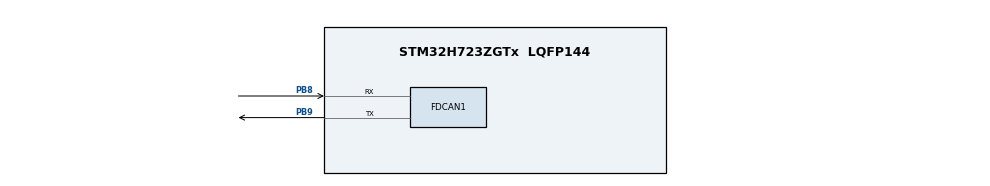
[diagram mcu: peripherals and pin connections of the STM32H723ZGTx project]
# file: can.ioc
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CORTEX_M7.default_mode_Activation=1
FDCAN1.CalculateBaudRateNominal=1000000
FDCAN1.CalculateTimeBitNominal=1000
FDCAN1.CalculateTimeQuantumNominal=41.666666666666664
FDCAN1.NominalPrescaler=2
FDCAN1.NominalTimeSeg1=20
FDCAN1.NominalTimeSeg2=3
FDCAN1.RxFifo0ElmtsNbr=8
FDCAN1.TxEventsNbr=4
FDCAN1.TxFifoQueueElmtsNbr=4
Mcu.Family=STM32H7
Mcu.Name=STM32H723ZGTx
Mcu.Package=LQFP144
NVIC.PriorityGroup=NVIC_PRIORITYGROUP_4
PB8.Mode=FDCAN_Activate
PB8.Signal=FDCAN1_RX
PB9.Mode=FDCAN_Activate
PB9.Signal=FDCAN1_TX
ProjectManager.HeapSize=0x200
ProjectManager.StackSize=0x400
ProjectManager.TargetToolchain=STM32CubeIDE
RCC.ADCFreq_Value=129000000
RCC.APB1Freq_Value=64000000
RCC.APB2Freq_Value=64000000
RCC.APB3Freq_Value=64000000
RCC.APB4Freq_Value=64000000
RCC.CortexFreq_Value=64000000
RCC.DIVM1=4
RCC.DIVN1=12
RCC.DIVQ1=4
RCC.HCLKFreq_Value=64000000
RCC.PLLFRACN=0
RCC.SYSCLKFreq_VALUE=64000000
RCC.USBFreq_Value=48000000
VP_MEMORYMAP_VS_MEMORYMAP.Mode=CurAppReg
board=custom

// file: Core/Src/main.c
/* USER CODE BEGIN Header */
/**
  ******************************************************************************
  * @file           : main.c
  * @brief          : Main program body
  ******************************************************************************
  * @attention
  *
  * Copyright (c) 2025 STMicroelectronics.
  * All rights reserved.
  *
  * This software is licensed under terms that can be found in the LICENSE file
  * in the root directory of this component.
  * If no LICENSE file comes with this software, it is provided AS-IS.
  *
  ******************************************************************************
  */
/* USER CODE END Header */
#include "main.h"

/* USER CODE BEGIN PD */

// Assuming the Transceiver Enable pin is on GPIOE Pin 7
// NOTE: You must verify this Pin/Port in your hardware schematic and CubeMX configuration.
#define CAN_TRANSCEIVER_EN_PORT    GPIOE
#define CAN_TRANSCEIVER_EN_PIN     GPIO_PIN_7 // <--- PIN CHANGED TO 7

/* USER CODE END PD */

FDCAN_HandleTypeDef hfdcan1;

/* USER CODE BEGIN PV */
// Define the FDCAN TxHeader structure globally
FDCAN_TxHeaderTypeDef TxHeader;

// Define a simple payload for transmission
uint8_t TxData[8] = {0x11, 0x22, 0x33, 0x44, 0x55, 0x66, 0x77, 0x88};
/* USER CODE END PV */

void SystemClock_Config(void);
static void MPU_Config(void);
static void MX_GPIO_Init(void);
static void MX_FDCAN1_Init(void);
/* USER CODE BEGIN PFP */
void CAN_Transmit_Message(uint32_t ID, uint8_t dlc, uint8_t *payload);
/* USER CODE END PFP */

/* USER CODE BEGIN 0 */

/**
  * @brief  Transmits a Classic CAN message.
  */
void CAN_Transmit_Message(uint32_t ID, uint8_t dlc, uint8_t *payload)
{
    // Configure the Header for Classic CAN
    TxHeader.Identifier = ID;
    TxHeader.IdType = FDCAN_STANDARD_ID;
    TxHeader.TxFrameType = FDCAN_DATA_FRAME;

    // Set Data Length Code (DLC) to 8 bytes
    TxHeader.DataLength = FDCAN_DLC_BYTES_8;

    // CRITICAL CLASSIC CAN SETTINGS
    TxHeader.FDFormat = FDCAN_CLASSIC_CAN;
    TxHeader.BitRateSwitch = FDCAN_BRS_OFF;

    TxHeader.ErrorStateIndicator = FDCAN_ESI_ACTIVE;
    TxHeader.TxEventFifoControl = FDCAN_NO_TX_EVENTS;
    TxHeader.MessageMarker = 0;

    // Add the message to the Transmission Queue
    if (HAL_FDCAN_AddMessageToTxFifoQ(&hfdcan1, &TxHeader, payload) != HAL_OK)
    {
        Error_Handler();
    }
}

/* USER CODE END 0 */

int main(void)
{

  /* MPU Configuration--------------------------------------------------------*/
  MPU_Config();

  /* MCU Configuration--------------------------------------------------------*/

  /* Reset of all peripherals, Initializes the Flash interface and the Systick. */
  HAL_Init();

  /* Configure the system clock */
  SystemClock_Config();

  /* Initialize all configured peripherals */
  MX_GPIO_Init();
  MX_FDCAN1_Init();
  /* USER CODE BEGIN 2 */
  // 1. Start the FDCAN controller
  if (HAL_FDCAN_Start(&hfdcan1) != HAL_OK)
    {
        Error_Handler();
    }

  // 2. Transceiver Enable: Set the CAN transceiver enable pin (GPIOE Pin 7) to LOW (GND)
  HAL_GPIO_WritePin(CAN_TRANSCEIVER_EN_PORT, CAN_TRANSCEIVER_EN_PIN, GPIO_PIN_RESET);
  /* USER CODE END 2 */

  /* Infinite loop */
  /* USER CODE BEGIN WHILE */
  FDCAN_ProtocolStatusTypeDef status; // Declare status variable here

  while (1)
  {
      // Check FDCAN status. If Bus-Off (BO bit set), attempt to reset and restart.
      HAL_FDCAN_GetProtocolStatus(&hfdcan1, &status);

      if (status.BusOff == 1)
      {
          // Bus-Off detected. Stop, delay, and restart FDCAN to clear the Bus-Off state.
          HAL_FDCAN_Stop(&hfdcan1);
          HAL_Delay(100);
          if (HAL_FDCAN_Start(&hfdcan1) != HAL_OK)
          {
              Error_Handler();
          }
      }

      // Transmit the CAN message
      CAN_Transmit_Message(0x123, 8, TxData);

      // Wait for 3 seconds (3000 milliseconds)
      HAL_Delay(3000);

    /* USER CODE END WHILE */

  }
}

void SystemClock_Config(void)
{
  RCC_OscInitTypeDef RCC_OscInitStruct = {0};
  RCC_ClkInitTypeDef RCC_ClkInitStruct = {0};

  /** Supply configuration update enable
  */
  HAL_PWREx_ConfigSupply(PWR_LDO_SUPPLY);

  /** Configure the main internal regulator output voltage
  */
  __HAL_PWR_VOLTAGESCALING_CONFIG(PWR_REGULATOR_VOLTAGE_SCALE3);

  while(!__HAL_PWR_GET_FLAG(PWR_FLAG_VOSRDY)) {}

  /** Initializes the RCC Oscillators according to the specified parameters
  * in the RCC_OscInitTypeDef structure.
  */
  RCC_OscInitStruct.OscillatorType = RCC_OSCILLATORTYPE_HSI;
  RCC_OscInitStruct.HSIState = RCC_HSI_DIV1;
  RCC_OscInitStruct.HSICalibrationValue = 64;
  RCC_OscInitStruct.PLL.PLLState = RCC_PLL_ON;
  RCC_OscInitStruct.PLL.PLLSource = RCC_PLLSOURCE_HSI;
  RCC_OscInitStruct.PLL.PLLM = 4;
  RCC_OscInitStruct.PLL.PLLN = 12;
  RCC_OscInitStruct.PLL.PLLP = 2;
  RCC_OscInitStruct.PLL.PLLQ = 4;
  RCC_OscInitStruct.PLL.PLLR = 2;
  RCC_OscInitStruct.PLL.PLLRGE = RCC_PLL1VCIRANGE_3;
  RCC_OscInitStruct.PLL.PLLVCOSEL = RCC_PLL1VCOWIDE;
  RCC_OscInitStruct.PLL.PLLFRACN = 0;
  if (HAL_RCC_OscConfig(&RCC_OscInitStruct) != HAL_OK)
  {
    Error_Handler();
  }

  /** Initializes the CPU, AHB and APB buses clocks
  */
  RCC_ClkInitStruct.ClockType = RCC_CLOCKTYPE_HCLK|RCC_CLOCKTYPE_SYSCLK
                              |RCC_CLOCKTYPE_PCLK1|RCC_CLOCKTYPE_PCLK2
                              |RCC_CLOCKTYPE_D3PCLK1|RCC_CLOCKTYPE_D1PCLK1;
  RCC_ClkInitStruct.SYSCLKSource = RCC_SYSCLKSOURCE_HSI;
  RCC_ClkInitStruct.SYSCLKDivider = RCC_SYSCLK_DIV1;
  RCC_ClkInitStruct.AHBCLKDivider = RCC_HCLK_DIV1;
  RCC_ClkInitStruct.APB3CLKDivider = RCC_APB3_DIV1;
  RCC_ClkInitStruct.APB1CLKDivider = RCC_APB1_DIV1;
  RCC_ClkInitStruct.APB2CLKDivider = RCC_APB2_DIV1;
  RCC_ClkInitStruct.APB4CLKDivider = RCC_APB4_DIV1;

  if (HAL_RCC_ClockConfig(&RCC_ClkInitStruct, FLASH_LATENCY_1) != HAL_OK)
  {
    Error_Handler();
  }
}

static void MX_FDCAN1_Init(void)
{

  hfdcan1.Instance = FDCAN1;
  hfdcan1.Init.FrameFormat = FDCAN_FRAME_CLASSIC;
  hfdcan1.Init.Mode = FDCAN_MODE_NORMAL;
  hfdcan1.Init.AutoRetransmission = DISABLE;
  hfdcan1.Init.TransmitPause = DISABLE;
  hfdcan1.Init.ProtocolException = DISABLE;
  // **Nominal Bit Timing Settings for 1 MBit/s with 48 MHz Clock (24 Tq, 87.5% SP)**
  hfdcan1.Init.NominalPrescaler = 2;
  hfdcan1.Init.NominalSyncJumpWidth = 3;
  hfdcan1.Init.NominalTimeSeg1 = 20;
  hfdcan1.Init.NominalTimeSeg2 = 3;
  // Data Bit Timing settings (used for CAN FD Data Phase, but must be configured)
  hfdcan1.Init.DataPrescaler = 1;
  hfdcan1.Init.DataSyncJumpWidth = 1;
  hfdcan1.Init.DataTimeSeg1 = 1;
  hfdcan1.Init.DataTimeSeg2 = 1;
  // Message RAM Configuration
  hfdcan1.Init.MessageRAMOffset = 0;
  hfdcan1.Init.StdFiltersNbr = 0;
  hfdcan1.Init.ExtFiltersNbr = 0;
  hfdcan1.Init.RxFifo0ElmtsNbr = 8;
  hfdcan1.Init.RxFifo0ElmtSize = FDCAN_DATA_BYTES_8;
  hfdcan1.Init.RxFifo1ElmtsNbr = 0;
  hfdcan1.Init.RxFifo1ElmtSize = FDCAN_DATA_BYTES_8;
  hfdcan1.Init.RxBuffersNbr = 0;
  hfdcan1.Init.RxBufferSize = FDCAN_DATA_BYTES_8;
  hfdcan1.Init.TxEventsNbr = 4;
  hfdcan1.Init.TxBuffersNbr = 0;
  hfdcan1.Init.TxFifoQueueElmtsNbr = 4;
  hfdcan1.Init.TxFifoQueueMode = FDCAN_TX_FIFO_OPERATION;
  hfdcan1.Init.TxElmtSize = FDCAN_DATA_BYTES_8;
  if (HAL_FDCAN_Init(&hfdcan1) != HAL_OK)
  {
    Error_Handler();
  }
  /* USER CODE BEGIN FDCAN1_Init 2 */

	  // NOTE: A wide filter is necessary to accept all incoming messages (or any message)
	  // and exit certain error/warning states on the bus.
	  FDCAN_FilterTypeDef sFilterConfig;
	  sFilterConfig.IdType = FDCAN_STANDARD_ID;
	  sFilterConfig.FilterIndex = 0;
	  sFilterConfig.FilterType = FDCAN_FILTER_RANGE;
	  sFilterConfig.FilterConfig = FDCAN_FILTER_TO_RXFIFO0;
	  sFilterConfig.FilterID1 = 0x000;    // Start of Standard ID range (0)
	  sFilterConfig.FilterID2 = 0x7FF;    // End of Standard ID range (2047)

	  if (HAL_FDCAN_ConfigFilter(&hfdcan1, &sFilterConfig) != HAL_OK)
	  {
	      Error_Handler();
	  }

  /* USER CODE END FDCAN1_Init 2 */

}

static void MX_GPIO_Init(void)
{
  GPIO_InitTypeDef GPIO_InitStruct = {0};

  /* GPIO Ports Clock Enable */
  __HAL_RCC_GPIOB_CLK_ENABLE();

  // CRITICAL FIX: Enable Clock for GPIOE (where Pin 7 is located)
  __HAL_RCC_GPIOE_CLK_ENABLE();

  // CRITICAL FIX: Configure Transceiver Enable Pin (GPIOE Pin 7) as Output
  GPIO_InitStruct.Pin = CAN_TRANSCEIVER_EN_PIN; // GPIO_PIN_7
  GPIO_InitStruct.Mode = GPIO_MODE_OUTPUT_PP;
  GPIO_InitStruct.Pull = GPIO_NOPULL;
  GPIO_InitStruct.Speed = GPIO_SPEED_FREQ_LOW;
  HAL_GPIO_Init(CAN_TRANSCEIVER_EN_PORT, &GPIO_InitStruct); // GPIOE

  // NOTE: Assuming FDCAN RX/TX pins (e.g., PB8/PB9) are configured elsewhere (e.g., CubeMX)

}

 /* MPU Configuration */

void MPU_Config(void)
{
  MPU_Region_InitTypeDef MPU_InitStruct = {0};

  /* Disables the MPU */
  HAL_MPU_Disable();

  /** Initializes and configures the Region and the memory to be protected
  */
  MPU_InitStruct.Enable = MPU_REGION_ENABLE;
  MPU_InitStruct.Number = MPU_REGION_NUMBER0;
  MPU_InitStruct.BaseAddress = 0x0;
  MPU_InitStruct.Size = MPU_REGION_SIZE_4GB;
  MPU_InitStruct.SubRegionDisable = 0x87;
  MPU_InitStruct.TypeExtField = MPU_TEX_LEVEL0;
  MPU_InitStruct.AccessPermission = MPU_REGION_NO_ACCESS;
  MPU_InitStruct.DisableExec = MPU_INSTRUCTION_ACCESS_DISABLE;
  MPU_InitStruct.IsShareable = MPU_ACCESS_SHAREABLE;
  MPU_InitStruct.IsCacheable = MPU_ACCESS_NOT_CACHEABLE;
  MPU_InitStruct.IsBufferable = MPU_ACCESS_NOT_BUFFERABLE;

  HAL_MPU_ConfigRegion(&MPU_InitStruct);
  /* Enables the MPU */
  HAL_MPU_Enable(MPU_PRIVILEGED_DEFAULT);

}

void Error_Handler(void)
{
  __disable_irq();
  while (1)
  {
  }
}
